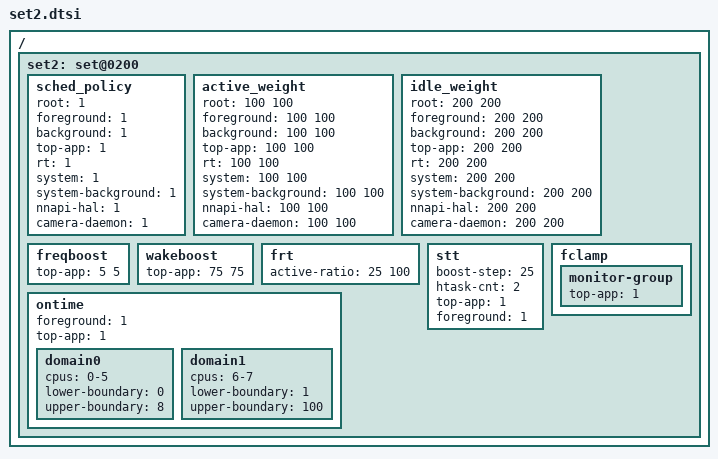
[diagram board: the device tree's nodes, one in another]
/ {
	/* performance mode - default */
	set2: set@0200 {
		sched_policy {
			root = <1>;
			foreground = <1>;
			background = <1>;
			top-app = <1>;
			rt = <1>;
			system = <1>;
			system-background = <1>;
			nnapi-hal = <1>;
			camera-daemon = <1>;
		};

		active_weight {
			root = <100 100>;
			foreground = <100 100>;
			background = <100 100>;
			top-app = <100 100>;
			rt = <100 100>;
			system = <100 100>;
			system-background = <100 100>;
			nnapi-hal = <100 100>;
			camera-daemon = <100 100>;
		};

		idle_weight {
			root = <200 200>;
			foreground = <200 200>;
			background = <200 200>;
			top-app = <200 200>;
			rt = <200 200>;
			system = <200 200>;
			system-background = <200 200>;
			nnapi-hal = <200 200>;
			camera-daemon = <200 200>;
		};

		/* Boosting margin applied to frequency selection */
		freqboost {			/* LIT BIG */
			top-app			= <  5   5>;
		};

		wakeboost {
			top-app = <75 75>;
		};

		frt {	   	     		/* LIT BIG */
			active-ratio		= < 25 100>;
		};

		/* Ontime Migration */
		ontime {
			foreground 	= <1>;
			top-app		= <1>;

			domain0 {
				cpus = "0-5";
				lower-boundary = <0>;
				upper-boundary = <8>;
			};
			domain1 {
				cpus = "6-7";
				lower-boundary = <1>;
				upper-boundary = <100>;
			};
		};

		stt {
			boost-step = <25>;
			htask-cnt = <2>;
			top-app = <1>;
			foreground = <1>;
		};

		fclamp {
			monitor-group {
				top-app         = <1>;
			};
		};
	};
};
